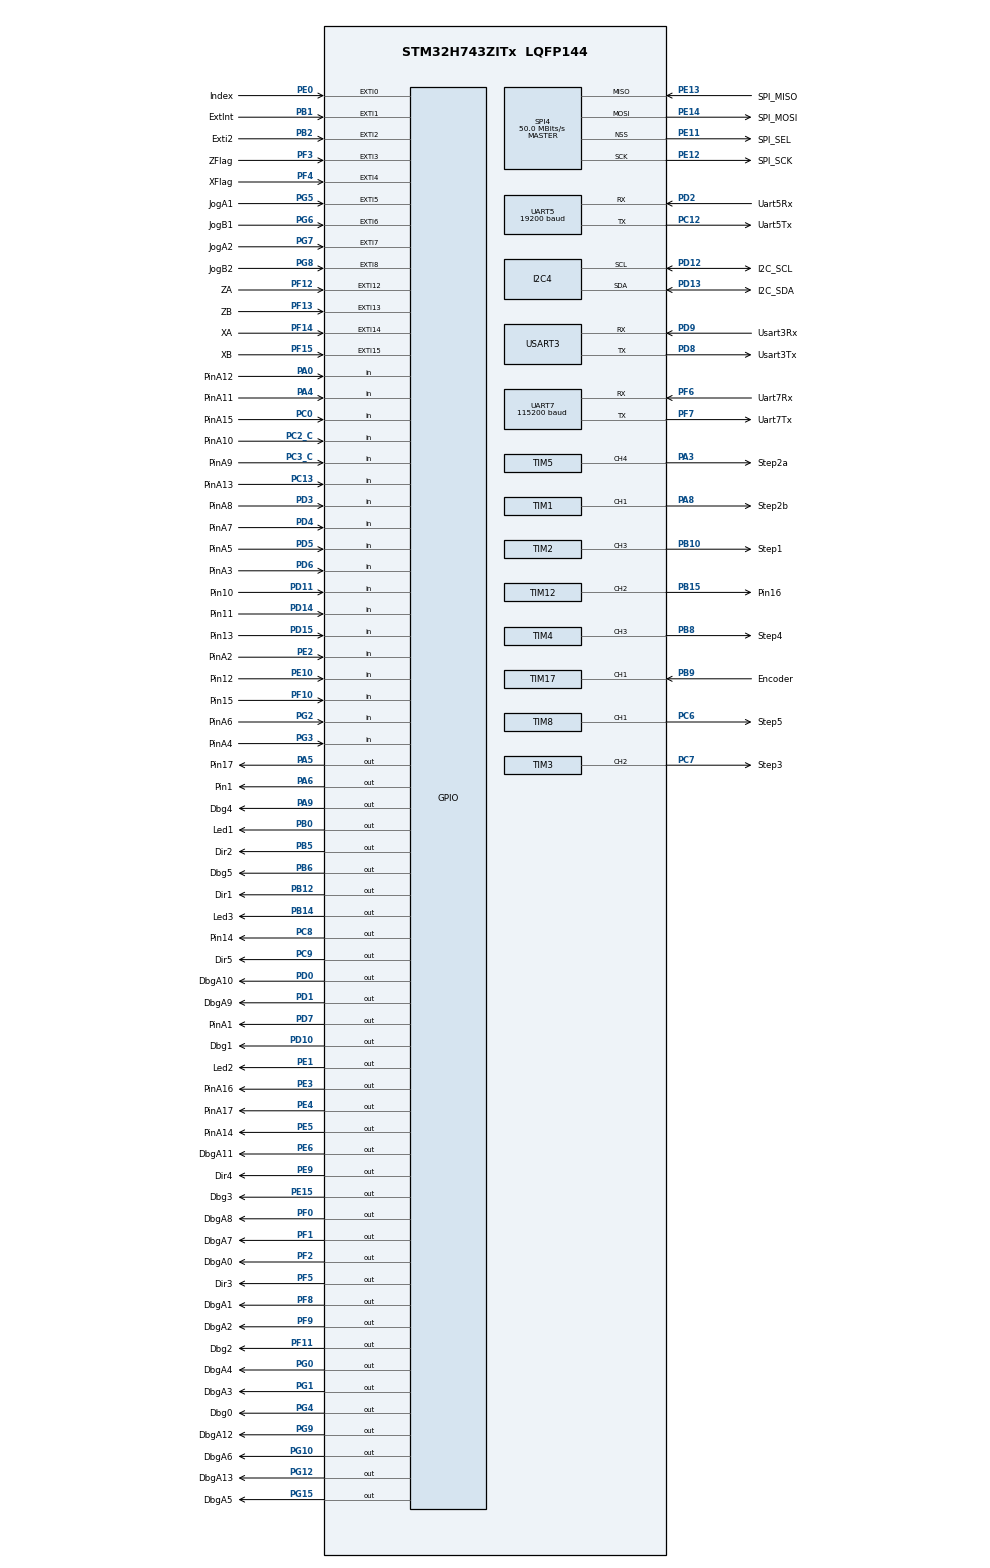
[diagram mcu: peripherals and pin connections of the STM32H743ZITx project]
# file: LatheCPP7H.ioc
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CORTEX_M7.CPU_DCache=Enabled
CORTEX_M7.CPU_ICache=Enabled
I2C4.Timing=0x10C0ECFF
IWDG1.Prescaler=IWDG_PRESCALER_256
Mcu.Family=STM32H7
Mcu.Name=STM32H743ZITx
Mcu.Package=LQFP144
NVIC.EXTI0_IRQn=true\:1\:0\:true\:false\:false\:true\:false\:false
NVIC.EXTI15_10_IRQn=true\:4\:0\:true\:false\:false\:true\:false\:false
NVIC.EXTI1_IRQn=true\:2\:0\:true\:false\:false\:true\:false\:false
NVIC.EXTI3_IRQn=true\:1\:0\:true\:false\:false\:true\:false\:false
NVIC.EXTI4_IRQn=true\:1\:0\:true\:false\:false\:true\:false\:false
NVIC.EXTI9_5_IRQn=true\:4\:0\:true\:false\:false\:true\:false\:false
NVIC.PriorityGroup=NVIC_PRIORITYGROUP_4
NVIC.TIM15_IRQn=true\:3\:0\:true\:false\:false\:true\:false\:true
NVIC.TIM16_IRQn=true\:3\:0\:true\:false\:false\:true\:false\:true
NVIC.TIM17_IRQn=true\:1\:0\:true\:false\:false\:true\:false\:true
NVIC.TIM1_UP_IRQn=true\:2\:0\:true\:false\:false\:true\:false\:true
NVIC.TIM2_IRQn=true\:2\:0\:true\:false\:false\:true\:false\:true
NVIC.TIM5_IRQn=true\:2\:0\:true\:false\:false\:true\:false\:true
NVIC.TIM8_BRK_TIM12_IRQn=true\:3\:0\:true\:false\:false\:true\:false\:true
NVIC.TIM8_UP_TIM13_IRQn=true\:2\:0\:true\:false\:false\:true\:false\:true
NVIC.UART5_IRQn=true\:3\:0\:true\:false\:false\:true\:false\:true
NVIC.UART7_IRQn=true\:3\:0\:true\:false\:false\:true\:false\:true
PA0.GPIO_Label=PinA12
PA0.Signal=GPIO_Input
PA11.GPIO_Label=USB_DM
PA11.Signal=USB_OTG_FS_DM
PA12.GPIO_Label=USB_DP
PA12.Signal=USB_OTG_FS_DP
PA13\ (JTMS/SWDIO).Mode=Trace_Asynchronous_SW
PA13\ (JTMS/SWDIO).Signal=DEBUG_JTMS-SWDIO
PA14\ (JTCK/SWCLK).Mode=Trace_Asynchronous_SW
PA14\ (JTCK/SWCLK).Signal=DEBUG_JTCK-SWCLK
PA3.GPIO_Label=Step2a
PA3.Signal=S_TIM5_CH4
PA4.GPIO_Label=PinA11
PA4.Signal=GPIO_Input
PA5.GPIO_Label=Pin17
PA5.Signal=GPIO_Output
PA6.GPIO_Label=Pin1
PA6.Signal=GPIO_Output
PA8.GPIO_Label=Step2b
PA8.Signal=S_TIM1_CH1
PA9.GPIO_Label=Dbg4
PA9.Signal=GPIO_Output
PB0.GPIO_Label=Led1
PB0.Signal=GPIO_Output
PB1.GPIO_Label=ExtInt
PB1.Signal=GPXTI1
PB10.GPIO_Label=Step1
PB10.Signal=S_TIM2_CH3
PB12.GPIO_Label=Dir1
PB12.Signal=GPIO_Output
PB14.GPIO_Label=Led3
PB14.Signal=GPIO_Output
PB15.GPIO_Label=Pin16
PB15.Signal=S_TIM12_CH2
PB2.GPIO_Label=Exti2
PB2.Signal=GPXTI2
PB3\ (JTDO/TRACESWO).Mode=Trace_Asynchronous_SW
PB3\ (JTDO/TRACESWO).Signal=DEBUG_JTDO-SWO
PB5.GPIO_Label=Dir2
PB5.Signal=GPIO_Output
PB6.GPIO_Label=Dbg5
PB6.Signal=GPIO_Output
PB8.GPIO_Label=Step4
PB8.Signal=S_TIM4_CH3
PB9.GPIO_Label=Encoder
PB9.Signal=S_TIM17_CH1
PC0.GPIO_Label=PinA15
PC0.Signal=GPIO_Input
PC12.GPIO_Label=Uart5Tx
PC12.Mode=Asynchronous
PC12.Signal=UART5_TX
PC13.GPIO_Label=PinA13
PC13.Signal=GPIO_Input
PC2_C.GPIO_Label=PinA10
PC2_C.Signal=GPIO_Input
PC3_C.GPIO_Label=PinA9
PC3_C.Signal=GPIO_Input
PC6.GPIO_Label=Step5
PC6.Signal=S_TIM8_CH1
PC7.GPIO_Label=Step3
PC7.Signal=S_TIM3_CH2
PC8.GPIO_Label=Pin14
PC8.Signal=GPIO_Output
PC9.GPIO_Label=Dir5
PC9.Signal=GPIO_Output
PD0.GPIO_Label=DbgA10
PD0.Signal=GPIO_Output
PD1.GPIO_Label=DbgA9
PD1.Signal=GPIO_Output
PD10.GPIO_Label=Dbg1
PD10.Signal=GPIO_Output
PD11.GPIO_Label=Pin10
PD11.Signal=GPIO_Input
PD12.GPIO_Label=I2C_SCL
PD12.GPIO_Pu=GPIO_PULLUP
PD12.Mode=I2C
PD12.Signal=I2C4_SCL
PD13.GPIO_Label=I2C_SDA
PD13.GPIO_Pu=GPIO_PULLUP
PD13.Mode=I2C
PD13.Signal=I2C4_SDA
PD14.GPIO_Label=Pin11
PD14.Signal=GPIO_Input
PD15.GPIO_Label=Pin13
PD15.Signal=GPIO_Input
PD2.GPIO_Label=Uart5Rx
PD2.Mode=Asynchronous
PD2.Signal=UART5_RX
PD3.GPIO_Label=PinA8
PD3.Signal=GPIO_Input
PD4.GPIO_Label=PinA7
PD4.Signal=GPIO_Input
PD5.GPIO_Label=PinA5
PD5.Signal=GPIO_Input
PD6.GPIO_Label=PinA3
PD6.Signal=GPIO_Input
PD7.GPIO_Label=PinA1
PD7.Signal=GPIO_Output
PD8.GPIO_Label=Usart3Tx
PD8.Mode=Asynchronous
PD8.Signal=USART3_TX
PD9.GPIO_Label=Usart3Rx
PD9.Mode=Asynchronous
PD9.Signal=USART3_RX
PE0.GPIO_Label=Index
PE0.Signal=GPXTI0
PE1.GPIO_Label=Led2
PE1.Signal=GPIO_Output
PE10.GPIO_Label=Pin12
PE10.Signal=GPIO_Input
PE11.GPIO_Label=SPI_SEL
PE11.Mode=NSS_Signal_Hard_Output
PE11.Signal=SPI4_NSS
PE12.GPIO_Label=SPI_SCK
PE12.Mode=Full_Duplex_Master
PE12.Signal=SPI4_SCK
PE13.GPIO_Label=SPI_MISO
PE13.Mode=Full_Duplex_Master
PE13.Signal=SPI4_MISO
PE14.GPIO_Label=SPI_MOSI
PE14.Mode=Full_Duplex_Master
PE14.Signal=SPI4_MOSI
PE15.GPIO_Label=Dbg3
PE15.Signal=GPIO_Output
PE2.GPIO_Label=PinA2
PE2.Signal=GPIO_Input
PE3.GPIO_Label=PinA16
PE3.Signal=GPIO_Output
PE4.GPIO_Label=PinA17
PE4.Signal=GPIO_Output
PE5.GPIO_Label=PinA14
PE5.Signal=GPIO_Output
PE6.GPIO_Label=DbgA11
PE6.Signal=GPIO_Output
PE9.GPIO_Label=Dir4
PE9.Signal=GPIO_Output
PF0.GPIO_Label=DbgA8
PF0.Signal=GPIO_Output
PF1.GPIO_Label=DbgA7
PF1.Signal=GPIO_Output
PF10.GPIO_Label=Pin15
PF10.Signal=GPIO_Input
PF11.GPIO_Label=Dbg2
PF11.Signal=GPIO_Output
PF12.GPIO_Label=ZA
PF12.GPIO_ModeDefaultEXTI=GPIO_MODE_IT_RISING_FALLING
PF12.Signal=GPXTI12
PF13.GPIO_Label=ZB
PF13.GPIO_ModeDefaultEXTI=GPIO_MODE_IT_RISING_FALLING
PF13.Signal=GPXTI13
PF14.GPIO_Label=XA
PF14.GPIO_ModeDefaultEXTI=GPIO_MODE_IT_RISING_FALLING
PF14.Signal=GPXTI14
PF15.GPIO_Label=XB
PF15.GPIO_ModeDefaultEXTI=GPIO_MODE_IT_RISING_FALLING
PF15.Signal=GPXTI15
PF2.GPIO_Label=DbgA0
PF2.Signal=GPIO_Output
PF3.GPIO_Label=ZFlag
PF3.Signal=GPXTI3
PF4.GPIO_Label=XFlag
PF4.Signal=GPXTI4
PF5.GPIO_Label=Dir3
PF5.Signal=GPIO_Output
PF6.GPIO_Label=Uart7Rx
PF6.Mode=Asynchronous
PF6.Signal=UART7_RX
PF7.GPIO_Label=Uart7Tx
PF7.Mode=Asynchronous
PF7.Signal=UART7_TX
PF8.GPIO_Label=DbgA1
PF8.Signal=GPIO_Output
PF9.GPIO_Label=DbgA2
PF9.Signal=GPIO_Output
PG0.GPIO_Label=DbgA4
PG0.Signal=GPIO_Output
PG1.GPIO_Label=DbgA3
PG1.Signal=GPIO_Output
PG10.GPIO_Label=DbgA6
PG10.Signal=GPIO_Output
PG12.GPIO_Label=DbgA13
PG12.Signal=GPIO_Output
PG15.GPIO_Label=DbgA5
PG15.Signal=GPIO_Output
PG2.GPIO_Label=PinA6
PG2.Signal=GPIO_Input
PG3.GPIO_Label=PinA4
PG3.Signal=GPIO_Input
PG4.GPIO_Label=Dbg0
PG4.Signal=GPIO_Output
PG5.GPIO_Label=JogA1
PG5.GPIO_ModeDefaultEXTI=GPIO_MODE_IT_RISING_FALLING
PG5.Signal=GPXTI5
PG6.GPIO_Label=JogB1
PG6.GPIO_ModeDefaultEXTI=GPIO_MODE_IT_RISING_FALLING
PG6.Signal=GPXTI6
PG7.GPIO_Label=JogA2
PG7.GPIO_ModeDefaultEXTI=GPIO_MODE_IT_RISING_FALLING
PG7.Signal=GPXTI7
PG8.GPIO_Label=JogB2
PG8.GPIO_ModeDefaultEXTI=GPIO_MODE_IT_RISING_FALLING
PG8.Signal=GPXTI8
PG9.GPIO_Label=DbgA12
PG9.Signal=GPIO_Output
PH0-OSC_IN\ (PH0).Mode=HSE-External-Clock-Source
PH0-OSC_IN\ (PH0).Signal=RCC_OSC_IN
ProjectManager.HeapSize=0x200
ProjectManager.StackSize=0x400
ProjectManager.TargetToolchain=STM32CubeIDE
RCC.ADCFreq_Value=16125000
RCC.APB1Freq_Value=100000000
RCC.APB2Freq_Value=100000000
RCC.APB3Freq_Value=100000000
RCC.APB4Freq_Value=100000000
RCC.CortexFreq_Value=400000000
RCC.D1PPRE=RCC_APB3_DIV2
RCC.D2PPRE1=RCC_APB1_DIV2
RCC.D2PPRE2=RCC_APB2_DIV2
RCC.D3PPRE=RCC_APB4_DIV2
RCC.DIVM1=1
RCC.DIVM3=1
RCC.DIVN1=100
RCC.DIVN3=24
RCC.DIVQ3=4
RCC.DIVR3=4
RCC.HCLKFreq_Value=200000000
RCC.HPRE=RCC_HCLK_DIV2
RCC.HSE_VALUE=8000000
RCC.PLLFRACN=0
RCC.PLLSourceVirtual=RCC_PLLSOURCE_HSE
RCC.PWR_Regulator_Voltage_Scale=PWR_REGULATOR_VOLTAGE_SCALE0
RCC.ProductRev=revV
RCC.SYSCLKFreq_VALUE=400000000
RCC.SYSCLKSource=RCC_SYSCLKSOURCE_PLLCLK
RCC.SupplySource=PWR_LDO_SUPPLY
RCC.USBCLockSelection=RCC_USBCLKSOURCE_PLL3
RCC.USBFreq_Value=48000000
SH.S_TIM12_CH2.0=TIM12_CH2,PWM Generation2 CH2
SH.S_TIM17_CH1.0=TIM17_CH1,Input_Capture1_from_TI1
SH.S_TIM1_CH1.0=TIM1_CH1,PWM Generation1 CH1
SH.S_TIM2_CH3.0=TIM2_CH3,PWM Generation3 CH3
SH.S_TIM3_CH2.0=TIM3_CH2,PWM Generation2 CH2
SH.S_TIM4_CH3.0=TIM4_CH3,PWM Generation3 CH3
SH.S_TIM5_CH4.0=TIM5_CH4,PWM Generation4 CH4
SH.S_TIM8_CH1.0=TIM8_CH1,PWM Generation1 CH1
SPI4.CalculateBaudRate=50.0 MBits/s
SPI4.Direction=SPI_DIRECTION_2LINES
SPI4.Mode=SPI_MODE_MASTER
SPI4.VirtualNSS=VM_NSSHARD
SPI4.VirtualType=VM_MASTER
TIM1.Channel-PWM\ Generation1\ CH1=TIM_CHANNEL_1
TIM12.Channel-PWM\ Generation2\ CH2=TIM_CHANNEL_2
TIM17.Channel=TIM_CHANNEL_1
TIM17.ICPolarity_CH1=TIM_INPUTCHANNELPOLARITY_BOTHEDGE
TIM2.Channel-PWM\ Generation3\ CH3=TIM_CHANNEL_3
TIM3.Channel-PWM\ Generation2\ CH2=TIM_CHANNEL_2
TIM4.Channel-PWM\ Generation3\ CH3=TIM_CHANNEL_3
TIM5.Channel-PWM\ Generation4\ CH4=TIM_CHANNEL_4
TIM8.Channel-PWM\ Generation1\ CH1=TIM_CHANNEL_1
UART5.BaudRate=19200
UART7.BaudRate=115200
USART3.VirtualMode-Asynchronous=VM_ASYNC
VP_IWDG1_VS_IWDG.Mode=IWDG_Activate
VP_TIM15_VS_ClockSourceINT.Mode=Internal
VP_TIM16_VS_ClockSourceINT.Mode=Enable_Timer
VP_TIM17_VS_ClockSourceINT.Mode=Enable_Timer
VP_TIM6_VS_ClockSourceINT.Mode=Enable_Timer
board=custom

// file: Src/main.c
/* USER CODE BEGIN Header */
/**
  ******************************************************************************
  * @file           : main.c
  * @brief          : Main program body
  ******************************************************************************
  * @attention
  *
  * <h2><center>&copy; Copyright (c) 2020 STMicroelectronics.
  * All rights reserved.</center></h2>
  *
  * This software component is licensed by ST under BSD 3-Clause license,
  * the "License"; You may not use this file except in compliance with the
  * License. You may obtain a copy of the License at:
  *                        opensource.org/licenses/BSD-3-Clause
  *
  ******************************************************************************
  */
/* USER CODE END Header */
#include "main.h"
#include "i2c.h"
#include "iwdg.h"
#include "spi.h"
#include "tim.h"
#include "usart.h"
#include "gpio.h"

void SystemClock_Config(void);

/* USER CODE BEGIN 0 */

#if defined(USB)
void usbClock_Config(void);
void usbInit(void);

int isrStart;
int isrEnd;
#endif  /* USB */

void mainLoop(void);

/* USER CODE END 0 */

int main(void)
{

  /* Enable I-Cache---------------------------------------------------------*/
  SCB_EnableICache();

  /* Enable D-Cache---------------------------------------------------------*/
  SCB_EnableDCache();

  /* MCU Configuration--------------------------------------------------------*/

  /* Reset of all peripherals, Initializes the Flash interface and the Systick. */
  HAL_Init();

  /* Configure the system clock */
  SystemClock_Config();

  /* USER CODE BEGIN SysInit */
#if defined(USB)
 usbClock_Config();
#endif  /* USB */
  /* USER CODE END SysInit */

  /* Initialize all configured peripherals */
  MX_GPIO_Init();
  MX_I2C4_Init();
  MX_SPI4_Init();
  MX_TIM1_Init();
  MX_TIM2_Init();
  MX_TIM3_Init();
  MX_TIM4_Init();
  MX_TIM5_Init();
  MX_TIM8_Init();
  MX_TIM12_Init();
  MX_TIM17_Init();
  MX_UART7_Init();
  MX_USART3_UART_Init();
  MX_TIM6_Init();
  MX_TIM15_Init();
  MX_TIM16_Init();
  MX_IWDG1_Init();
  MX_UART5_Init();
  /* USER CODE BEGIN 2 */

#if defined(USB)

 usbInit();
 HAL_PWREx_EnableUSBVoltageDetector();
 __HAL_RCC_USB2_OTG_FS_CLK_ENABLE();

#endif  /* USB */

  mainLoop();

  /* USER CODE END 2 */

  /* Infinite loop */
  while (1)
  {

  }
}

void SystemClock_Config(void)
{
  RCC_OscInitTypeDef RCC_OscInitStruct = {0};
  RCC_ClkInitTypeDef RCC_ClkInitStruct = {0};

  /** Supply configuration update enable
  */
  HAL_PWREx_ConfigSupply(PWR_LDO_SUPPLY);

  /** Configure the main internal regulator output voltage
  */
  __HAL_PWR_VOLTAGESCALING_CONFIG(PWR_REGULATOR_VOLTAGE_SCALE1);

  while(!__HAL_PWR_GET_FLAG(PWR_FLAG_VOSRDY)) {}

  __HAL_RCC_SYSCFG_CLK_ENABLE();
  __HAL_PWR_VOLTAGESCALING_CONFIG(PWR_REGULATOR_VOLTAGE_SCALE0);

  while(!__HAL_PWR_GET_FLAG(PWR_FLAG_VOSRDY)) {}

  /** Initializes the RCC Oscillators according to the specified parameters
  * in the RCC_OscInitTypeDef structure.
  */
  RCC_OscInitStruct.OscillatorType = RCC_OSCILLATORTYPE_LSI|RCC_OSCILLATORTYPE_HSE;
  RCC_OscInitStruct.HSEState = RCC_HSE_BYPASS;
  RCC_OscInitStruct.LSIState = RCC_LSI_ON;
  RCC_OscInitStruct.PLL.PLLState = RCC_PLL_ON;
  RCC_OscInitStruct.PLL.PLLSource = RCC_PLLSOURCE_HSE;
  RCC_OscInitStruct.PLL.PLLM = 1;
  RCC_OscInitStruct.PLL.PLLN = 100;
  RCC_OscInitStruct.PLL.PLLP = 2;
  RCC_OscInitStruct.PLL.PLLQ = 2;
  RCC_OscInitStruct.PLL.PLLR = 2;
  RCC_OscInitStruct.PLL.PLLRGE = RCC_PLL1VCIRANGE_3;
  RCC_OscInitStruct.PLL.PLLVCOSEL = RCC_PLL1VCOWIDE;
  RCC_OscInitStruct.PLL.PLLFRACN = 0;
  if (HAL_RCC_OscConfig(&RCC_OscInitStruct) != HAL_OK)
  {
    Error_Handler();
  }

  /** Initializes the CPU, AHB and APB buses clocks
  */
  RCC_ClkInitStruct.ClockType = RCC_CLOCKTYPE_HCLK|RCC_CLOCKTYPE_SYSCLK
                              |RCC_CLOCKTYPE_PCLK1|RCC_CLOCKTYPE_PCLK2
                              |RCC_CLOCKTYPE_D3PCLK1|RCC_CLOCKTYPE_D1PCLK1;
  RCC_ClkInitStruct.SYSCLKSource = RCC_SYSCLKSOURCE_PLLCLK;
  RCC_ClkInitStruct.SYSCLKDivider = RCC_SYSCLK_DIV1;
  RCC_ClkInitStruct.AHBCLKDivider = RCC_HCLK_DIV2;
  RCC_ClkInitStruct.APB3CLKDivider = RCC_APB3_DIV2;
  RCC_ClkInitStruct.APB1CLKDivider = RCC_APB1_DIV2;
  RCC_ClkInitStruct.APB2CLKDivider = RCC_APB2_DIV2;
  RCC_ClkInitStruct.APB4CLKDivider = RCC_APB4_DIV2;

  if (HAL_RCC_ClockConfig(&RCC_ClkInitStruct, FLASH_LATENCY_2) != HAL_OK)
  {
    Error_Handler();
  }
}

/* USER CODE BEGIN 4 */

#if defined(USB)

void usbClock_Config(void)
{
 RCC_PeriphCLKInitTypeDef PeriphClkInitStruct = {0};

 PeriphClkInitStruct.PeriphClockSelection = RCC_PERIPHCLK_USB;
 PeriphClkInitStruct.PLL3.PLL3M = 1;
 PeriphClkInitStruct.PLL3.PLL3N = 24;
 PeriphClkInitStruct.PLL3.PLL3P = 2;
 PeriphClkInitStruct.PLL3.PLL3Q = 4;
 PeriphClkInitStruct.PLL3.PLL3R = 2;
 PeriphClkInitStruct.PLL3.PLL3RGE = RCC_PLL3VCIRANGE_3;
 PeriphClkInitStruct.PLL3.PLL3FRACN = 0;
 PeriphClkInitStruct.UsbClockSelection = RCC_USBCLKSOURCE_PLL3;

 if (HAL_RCCEx_PeriphCLKConfig(&PeriphClkInitStruct) != HAL_OK) {
  Error_Handler();
 }
}

void usbInit(void)
{
 GPIO_InitTypeDef GPIO_InitStruct;

 GPIO_InitStruct.Pin = USB_DM_Pin | USB_DP_Pin;
 GPIO_InitStruct.Speed = GPIO_SPEED_FREQ_HIGH;
 GPIO_InitStruct.Mode = GPIO_MODE_AF_PP;
 GPIO_InitStruct.Pull = GPIO_NOPULL;
 GPIO_InitStruct.Alternate = GPIO_AF10_OTG2_HS;
 HAL_GPIO_Init(USB_DM_GPIO_Port, &GPIO_InitStruct);
}

#endif  /* USB */

/* USER CODE END 4 */

void Error_Handler(void)
{
}
